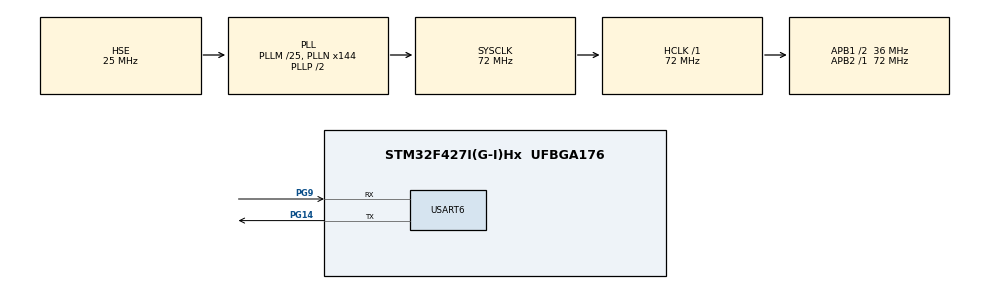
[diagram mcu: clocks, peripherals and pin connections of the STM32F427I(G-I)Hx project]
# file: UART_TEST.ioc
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Mcu.Family=STM32F4
Mcu.Name=STM32F427I(G-I)Hx
Mcu.Package=UFBGA176
NVIC.PriorityGroup=NVIC_PRIORITYGROUP_4
NVIC.USART6_IRQn=true\:0\:0\:false\:false\:true\:true\:true
PG14.GPIO_PuPd=GPIO_PULLUP
PG14.GPIO_Speed=GPIO_SPEED_FREQ_HIGH
PG14.Mode=Asynchronous
PG14.Signal=USART6_TX
PG9.GPIO_PuPd=GPIO_PULLUP
PG9.GPIO_Speed=GPIO_SPEED_FREQ_HIGH
PG9.Mode=Asynchronous
PG9.Signal=USART6_RX
PH0/OSC_IN.Mode=HSE-External-Oscillator
PH0/OSC_IN.Signal=RCC_OSC_IN
PH1/OSC_OUT.Mode=HSE-External-Oscillator
PH1/OSC_OUT.Signal=RCC_OSC_OUT
ProjectManager.HeapSize=0x200
ProjectManager.StackSize=0x400
ProjectManager.TargetToolchain=MDK-ARM V5
RCC.48MHZClocksFreq_Value=36000000
RCC.AHBFreq_Value=72000000
RCC.APB1CLKDivider=RCC_HCLK_DIV2
RCC.APB1Freq_Value=36000000
RCC.APB1TimFreq_Value=72000000
RCC.APB2Freq_Value=72000000
RCC.APB2TimFreq_Value=72000000
RCC.CortexFreq_Value=72000000
RCC.HCLKFreq_Value=72000000
RCC.HSE_VALUE=25000000
RCC.HSI_VALUE=16000000
RCC.LSE_VALUE=32768
RCC.PLLM=25
RCC.PLLN=144
RCC.PLLSourceVirtual=RCC_PLLSOURCE_HSE
RCC.SYSCLKFreq_VALUE=72000000
RCC.SYSCLKSource=RCC_SYSCLKSOURCE_PLLCLK
RCC.VCOOutputFreq_Value=144000000
USART6.VirtualMode=VM_ASYNC
board=custom

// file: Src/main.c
/* USER CODE BEGIN Header */
/**
  ******************************************************************************
  * @file           : main.c
  * @brief          : Main program body
  ******************************************************************************
  * @attention
  *
  * <h2><center>&copy; Copyright (c) 2021 STMicroelectronics.
  * All rights reserved.</center></h2>
  *
  * This software component is licensed by ST under BSD 3-Clause license,
  * the "License"; You may not use this file except in compliance with the
  * License. You may obtain a copy of the License at:
  *                        opensource.org/licenses/BSD-3-Clause
  *
  ******************************************************************************
  */
/* USER CODE END Header */
#include "main.h"
#include "usart.h"
#include "gpio.h"

/* USER CODE BEGIN PV */
uint8_t data;
uint8_t pBuffer = 0;
uint8_t Buffer[15];

uint32_t timer;

/* USER CODE END PV */

void SystemClock_Config(void);

int main(void)
{

  /* MCU Configuration--------------------------------------------------------*/

  /* Reset of all peripherals, Initializes the Flash interface and the Systick. */
  HAL_Init();

  /* Configure the system clock */
  SystemClock_Config();

  /* Initialize all configured peripherals */
  MX_GPIO_Init();
  MX_USART6_UART_Init();
  /* USER CODE BEGIN 2 */
	HAL_UART_Receive_IT(&huart6, &data, 1);
	timer = HAL_GetTick();
  /* USER CODE END 2 */

  /* Infinite loop */
  /* USER CODE BEGIN WHILE */
  while (1)
  {
		uint8_t test = 0x27;
		HAL_UART_Transmit(&huart6, &test, 1, 0xFFFF);
		HAL_Delay(100);
    /* USER CODE END WHILE */

  }
}

void SystemClock_Config(void)
{
  RCC_OscInitTypeDef RCC_OscInitStruct = {0};
  RCC_ClkInitTypeDef RCC_ClkInitStruct = {0};

  /** Configure the main internal regulator output voltage
  */
  __HAL_RCC_PWR_CLK_ENABLE();
  __HAL_PWR_VOLTAGESCALING_CONFIG(PWR_REGULATOR_VOLTAGE_SCALE3);
  /** Initializes the RCC Oscillators according to the specified parameters
  * in the RCC_OscInitTypeDef structure.
  */
  RCC_OscInitStruct.OscillatorType = RCC_OSCILLATORTYPE_HSE;
  RCC_OscInitStruct.HSEState = RCC_HSE_ON;
  RCC_OscInitStruct.PLL.PLLState = RCC_PLL_ON;
  RCC_OscInitStruct.PLL.PLLSource = RCC_PLLSOURCE_HSE;
  RCC_OscInitStruct.PLL.PLLM = 25;
  RCC_OscInitStruct.PLL.PLLN = 144;
  RCC_OscInitStruct.PLL.PLLP = RCC_PLLP_DIV2;
  RCC_OscInitStruct.PLL.PLLQ = 4;
  if (HAL_RCC_OscConfig(&RCC_OscInitStruct) != HAL_OK)
  {
    Error_Handler();
  }
  /** Initializes the CPU, AHB and APB buses clocks
  */
  RCC_ClkInitStruct.ClockType = RCC_CLOCKTYPE_HCLK|RCC_CLOCKTYPE_SYSCLK
                              |RCC_CLOCKTYPE_PCLK1|RCC_CLOCKTYPE_PCLK2;
  RCC_ClkInitStruct.SYSCLKSource = RCC_SYSCLKSOURCE_PLLCLK;
  RCC_ClkInitStruct.AHBCLKDivider = RCC_SYSCLK_DIV1;
  RCC_ClkInitStruct.APB1CLKDivider = RCC_HCLK_DIV2;
  RCC_ClkInitStruct.APB2CLKDivider = RCC_HCLK_DIV1;

  if (HAL_RCC_ClockConfig(&RCC_ClkInitStruct, FLASH_LATENCY_2) != HAL_OK)
  {
    Error_Handler();
  }
}

/* USER CODE BEGIN 4 */
/*
void HAL_UART_RxCpltCallback(UART_HandleTypeDef *huart){
	if(huart->Instance == USART6){
		Buffer[pBuffer++] = data;
		//uint8_t test = 0x23;
		//HAL_UART_Transmit(&huart6, &test, 1, 0xFFFF);
		while(HAL_UART_GetState(&huart6) == HAL_UART_STATE_BUSY_TX);
		// if: buffer full or read "0D 0A" or pass 1 sec
		if(pBuffer >= 15 || (pBuffer >= 2 && Buffer[pBuffer-2] == 0x0D && Buffer[pBuffer-1] == 0x0A) || HAL_GetTick() - timer > 1000){
			timer = HAL_GetTick();
			// HAL_UART_Transmit(&huart6, Buffer, pBuffer, 0xFFFF);
			while(HAL_UART_GetState(&huart6) == HAL_UART_STATE_BUSY_TX);
			pBuffer = 0;
		}
	}
}
*/
/* USER CODE END 4 */

void Error_Handler(void)
{
  __disable_irq();
  while (1)
  {
  }
}

/************************ (C) COPYRIGHT STMicroelectronics *****END OF FILE****/
